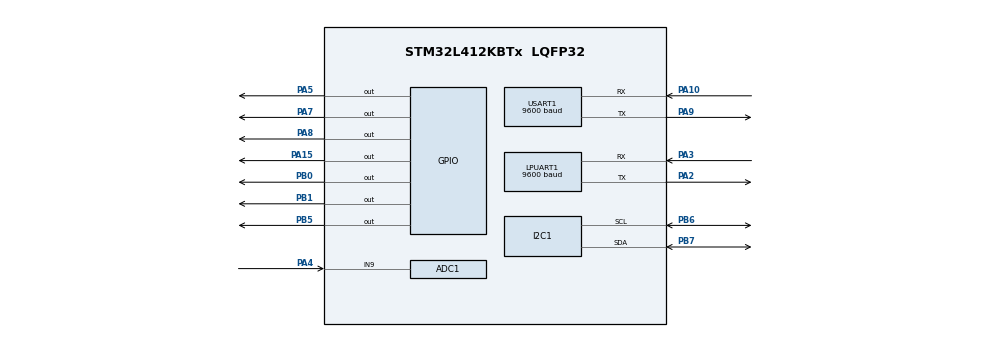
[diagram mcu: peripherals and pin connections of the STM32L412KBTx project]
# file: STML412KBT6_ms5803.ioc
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ADC1.Channel-0\#ChannelRegularConversion=ADC_CHANNEL_9
ADC1.NbrOfConversionFlag=1
ADC1.OffsetNumber-0\#ChannelRegularConversion=ADC_OFFSET_NONE
ADC1.Rank-0\#ChannelRegularConversion=1
ADC1.SamplingTime-0\#ChannelRegularConversion=ADC_SAMPLETIME_2CYCLES_5
ADC1.master=1
I2C1.Timing=0x10D19CE4
LPUART1.BaudRate=9600
LPUART1.WordLength=UART_WORDLENGTH_8B
Mcu.Family=STM32L4
Mcu.Name=STM32L412KBTx
Mcu.Package=LQFP32
NVIC.I2C1_ER_IRQn=true\:0\:0\:false\:false\:true\:true\:true\:true
NVIC.I2C1_EV_IRQn=true\:0\:0\:false\:false\:true\:true\:true\:true
NVIC.LPUART1_IRQn=true\:0\:0\:false\:false\:true\:true\:true\:true
NVIC.PriorityGroup=NVIC_PRIORITYGROUP_4
NVIC.RTC_Alarm_IRQn=true\:0\:0\:false\:false\:true\:true\:true\:true
NVIC.USART1_IRQn=true\:0\:0\:false\:false\:true\:true\:true\:true
PA10.Mode=Asynchronous
PA10.Signal=USART1_RX
PA15\ (JTDI).Signal=GPIO_Output
PA2.Mode=Asynchronous
PA2.Signal=LPUART1_TX
PA3.Mode=Asynchronous
PA3.Signal=LPUART1_RX
PA4.Signal=ADCx_IN9
PA5.Signal=GPIO_Output
PA7.Signal=GPIO_Output
PA8.Signal=GPIO_Output
PA9.Mode=Asynchronous
PA9.Signal=USART1_TX
PB0.Signal=GPIO_Output
PB1.Signal=GPIO_Output
PB5.Signal=GPIO_Output
PB6.Mode=I2C
PB6.Signal=I2C1_SCL
PB7.Mode=I2C
PB7.Signal=I2C1_SDA
PC14-OSC32_IN\ (PC14).Mode=LSE-External-Oscillator
PC14-OSC32_IN\ (PC14).Signal=RCC_OSC32_IN
PC15-OSC32_OUT\ (PC15).Mode=LSE-External-Oscillator
PC15-OSC32_OUT\ (PC15).Signal=RCC_OSC32_OUT
ProjectManager.HeapSize=0x200
ProjectManager.StackSize=0x400
ProjectManager.TargetToolchain=Makefile
RCC.ADCFreq_Value=80000000
RCC.AHBFreq_Value=80000000
RCC.APB1Freq_Value=80000000
RCC.APB1TimFreq_Value=80000000
RCC.APB2Freq_Value=80000000
RCC.APB2TimFreq_Value=80000000
RCC.CortexFreq_Value=80000000
RCC.HCLKFreq_Value=80000000
RCC.HSE_VALUE=8000000
RCC.HSI48_VALUE=48000000
RCC.HSI_VALUE=16000000
RCC.LPUART1CLockSelection=RCC_LPUART1CLKSOURCE_HSI
RCC.MSI_VALUE=4000000
RCC.PLLM=2
RCC.PLLN=20
RCC.PLLSourceVirtual=RCC_PLLSOURCE_HSI
RCC.RTCClockSelection=RCC_RTCCLKSOURCE_LSE
RCC.SYSCLKFreq_VALUE=80000000
RCC.SYSCLKSource=RCC_SYSCLKSOURCE_PLLCLK
RCC.USBFreq_Value=4000000
RCC.VCOOutputFreq_Value=160000000
RTC.Alarm=RTC_ALARM_A
SH.ADCx_IN9.0=ADC1_IN9,IN9-Single-Ended
USART1.BaudRate=9600
USART1.VirtualMode-Asynchronous=VM_ASYNC
VP_RTC_VS_RTC_Activate.Mode=RTC_Enabled
VP_RTC_VS_RTC_Alarm_A_Intern.Mode=Alarm A
VP_RTC_VS_RTC_Calendar.Mode=RTC_Calendar
board=custom

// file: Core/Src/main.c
/* USER CODE BEGIN Header */
/**
 ******************************************************************************
 * @file           : main.c
 * @brief          : Main program body
 ******************************************************************************
 * @attention
 *
 * Copyright (c) 2024 STMicroelectronics.
 * All rights reserved.
 *
 * This software is licensed under terms that can be found in the LICENSE file
 * in the root directory of this software component.
 * If no LICENSE file comes with this software, it is provided AS-IS.
 *
 ******************************************************************************
 */
/* USER CODE END Header */
#include "main.h"
#include "rtc.h"
#include "flash.h"
/* USER CODE BEGIN Includes */

  static void MX_GPIO_Init(void);
  static void MX_I2C1_Init(void);
  static void MX_ADC1_Init(void);
  static void MX_USART1_UART_Init(void);
  static void MX_LPUART1_UART_Init(void);
  static void MX_IWDG_Init(void);

  // 添加头文件
#include <stdio.h>

typedef enum {
    COLD_BOOT = 0,
    WAKEUP_FROM_PA0,
    WAKEUP_FROM_RTC,
    WAKEUP_FROM_UNKNOWN
} wakeup_source_t;

wakeup_source_t check_wakeup_source(void)
{
    // 必须先使能PWR时钟才能读取标志
    LL_APB1_GRP1_EnableClock(LL_APB1_GRP1_PERIPH_PWR);

    // 检查Standby唤醒标志
    if (LL_PWR_IsActiveFlag_SB() != RESET) {
        // 检查具体的唤醒源
        if (LL_PWR_IsActiveFlag_WU1() != RESET) {
            LL_PWR_ClearFlag_WU1();
            LL_PWR_ClearFlag_SB();
            return WAKEUP_FROM_PA0;
        }
        else if (LL_RTC_IsActiveFlag_ALRA(RTC) != RESET) {
            LL_RTC_ClearFlag_ALRA(RTC);
            LL_PWR_ClearFlag_SB();
            return WAKEUP_FROM_RTC;
        }
        else {
            LL_PWR_ClearFlag_SB();
            return WAKEUP_FROM_UNKNOWN;
        }
    }

    return COLD_BOOT;
}

#include "flash_test.h"

uint8_t wakeup_source = 0;
int main(void)
{
  /* MCU配置部分保持不变 */
    LL_APB2_GRP1_EnableClock(LL_APB2_GRP1_PERIPH_SYSCFG);
    LL_APB1_GRP1_EnableClock(LL_APB1_GRP1_PERIPH_PWR);

    /* 系统中断配置 */
    NVIC_SetPriorityGrouping(NVIC_PRIORITYGROUP_4);
    NVIC_SetPriority(SysTick_IRQn, NVIC_EncodePriority(NVIC_GetPriorityGrouping(),15, 0));

    /* 1. 首先检查唤醒源 - 必须在任何外设初始化之前 */
    wakeup_source = check_wakeup_source();

    /* 2. 配置系统时钟 */
    SystemClock_Config();

    /* 3. 初始化必要的外设 */
    MX_GPIO_Init();
    MX_I2C1_Init();
    MX_ADC1_Init();
    MX_USART1_UART_Init();
    MX_LPUART1_UART_Init();
    MX_RTC_Init();  // 取消注释
    LL_GPIO_ResetOutputPin(GPIOB, LL_GPIO_PIN_1);
    /* 主循环 */
    initial_application();
    while (1)
    {
        exec();
    }
}

void SystemClock_Config(void)
{
  volatile uint32_t i;
  for(i = 0; i < 100000; i++);  // 约10ms延迟
  LL_FLASH_SetLatency(LL_FLASH_LATENCY_4);
  while(LL_FLASH_GetLatency()!= LL_FLASH_LATENCY_4)
  {
  }
  LL_PWR_SetRegulVoltageScaling(LL_PWR_REGU_VOLTAGE_SCALE1);
  while (LL_PWR_IsActiveFlag_VOS() != 0)
  {
  }
  LL_RCC_HSI_Enable();

   /* Wait till HSI is ready */
  while(LL_RCC_HSI_IsReady() != 1)
  {

  }
  LL_RCC_HSI_SetCalibTrimming(64);
  LL_PWR_EnableBkUpAccess();
  LL_RCC_LSE_SetDriveCapability(LL_RCC_LSEDRIVE_LOW);
  LL_RCC_LSE_Enable();

   /* Wait till LSE is ready */
  while(LL_RCC_LSE_IsReady() != 1)
  {

  }
  LL_RCC_PLL_ConfigDomain_SYS(LL_RCC_PLLSOURCE_HSI, LL_RCC_PLLM_DIV_2, 20, LL_RCC_PLLR_DIV_2);
  LL_RCC_PLL_EnableDomain_SYS();
  LL_RCC_PLL_Enable();

   /* Wait till PLL is ready */
  while(LL_RCC_PLL_IsReady() != 1)
  {

  }
  LL_RCC_SetSysClkSource(LL_RCC_SYS_CLKSOURCE_PLL);

   /* Wait till System clock is ready */
  while(LL_RCC_GetSysClkSource() != LL_RCC_SYS_CLKSOURCE_STATUS_PLL)
  {

  }
  LL_RCC_SetAHBPrescaler(LL_RCC_SYSCLK_DIV_1);
  LL_RCC_SetAPB1Prescaler(LL_RCC_APB1_DIV_1);
  LL_RCC_SetAPB2Prescaler(LL_RCC_APB2_DIV_1);

  // 添加LPUART时钟源配置
  LL_RCC_SetLPUARTClockSource(LL_RCC_LPUART1_CLKSOURCE_PCLK1);

  LL_Init1msTick(80000000);

  LL_SetSystemCoreClock(80000000);
  // 启用SysTick中断
  LL_SYSTICK_EnableIT();

}

static void MX_ADC1_Init(void)
{

  LL_ADC_InitTypeDef ADC_InitStruct = {0};
  LL_ADC_REG_InitTypeDef ADC_REG_InitStruct = {0};
  LL_ADC_CommonInitTypeDef ADC_CommonInitStruct = {0};

  LL_GPIO_InitTypeDef GPIO_InitStruct = {0};

  /* Peripheral clock enable */
  LL_AHB2_GRP1_EnableClock(LL_AHB2_GRP1_PERIPH_ADC);

  LL_AHB2_GRP1_EnableClock(LL_AHB2_GRP1_PERIPH_GPIOA);
  /**ADC1 GPIO Configuration
  PA4   ------> ADC1_IN9
  */
  GPIO_InitStruct.Pin = LL_GPIO_PIN_4;
  GPIO_InitStruct.Mode = LL_GPIO_MODE_ANALOG;
  GPIO_InitStruct.Pull = LL_GPIO_PULL_NO;
  LL_GPIO_Init(GPIOA, &GPIO_InitStruct);

  // LL_GPIO_EnablePinAnalogControl(GPIOA,LL_GPIO_PIN_4);

  /** Common config
  */
  ADC_InitStruct.Resolution = LL_ADC_RESOLUTION_12B;
  ADC_InitStruct.DataAlignment = LL_ADC_DATA_ALIGN_RIGHT;
  ADC_InitStruct.LowPowerMode = LL_ADC_LP_MODE_NONE;
  LL_ADC_Init(ADC1, &ADC_InitStruct);
  ADC_REG_InitStruct.TriggerSource = LL_ADC_REG_TRIG_SOFTWARE;
  ADC_REG_InitStruct.SequencerLength = LL_ADC_REG_SEQ_SCAN_DISABLE;
  ADC_REG_InitStruct.SequencerDiscont = LL_ADC_REG_SEQ_DISCONT_DISABLE;
  ADC_REG_InitStruct.ContinuousMode = LL_ADC_REG_CONV_SINGLE;
  ADC_REG_InitStruct.DMATransfer = LL_ADC_REG_DMA_TRANSFER_NONE;
  ADC_REG_InitStruct.Overrun = LL_ADC_REG_OVR_DATA_PRESERVED;
  LL_ADC_REG_Init(ADC1, &ADC_REG_InitStruct);
  LL_ADC_SetOverSamplingScope(ADC1, LL_ADC_OVS_DISABLE);
  ADC_CommonInitStruct.CommonClock = LL_ADC_CLOCK_ASYNC_DIV2;
  ADC_CommonInitStruct.Multimode = LL_ADC_MULTI_INDEPENDENT;
  LL_ADC_CommonInit(__LL_ADC_COMMON_INSTANCE(ADC1), &ADC_CommonInitStruct);
  LL_ADC_SetCommonPathInternalCh(__LL_ADC_COMMON_INSTANCE(ADC1), LL_ADC_PATH_INTERNAL_NONE);

  /* Disable ADC deep power down (enabled by default after reset state) */
  LL_ADC_DisableDeepPowerDown(ADC1);
  /* Enable ADC internal voltage regulator */
  LL_ADC_EnableInternalRegulator(ADC1);
  /* Delay for ADC internal voltage regulator stabilization. */
  /* Compute number of CPU cycles to wait for, from delay in us. */
  /* Note: Variable divided by 2 to compensate partially */
  /* CPU processing cycles (depends on compilation optimization). */
  /* Note: If system core clock frequency is below 200kHz, wait time */
  /* is only a few CPU processing cycles. */
  uint32_t wait_loop_index;
  wait_loop_index = ((LL_ADC_DELAY_INTERNAL_REGUL_STAB_US * (SystemCoreClock / (100000 * 2))) / 10);
  while(wait_loop_index != 0)
  {
    wait_loop_index--;
  }

  /** Configure Regular Channel
  */
  LL_ADC_REG_SetSequencerRanks(ADC1, LL_ADC_REG_RANK_1, LL_ADC_CHANNEL_9);
  LL_ADC_SetChannelSamplingTime(ADC1, LL_ADC_CHANNEL_9, LL_ADC_SAMPLINGTIME_47CYCLES_5);
  LL_ADC_SetChannelSingleDiff(ADC1, LL_ADC_CHANNEL_9, LL_ADC_SINGLE_ENDED);
  /* USER CODE BEGIN ADC1_Init 2 */
  LL_ADC_StartCalibration(ADC1,LL_ADC_SINGLE_ENDED);
  /* USER CODE END ADC1_Init 2 */
}

static void MX_I2C1_Init(void)
{
  /* USER CODE END I2C1_Init 0 */

  LL_I2C_InitTypeDef I2C_InitStruct = {0};

  LL_GPIO_InitTypeDef GPIO_InitStruct = {0};

  LL_RCC_SetI2CClockSource(LL_RCC_I2C1_CLKSOURCE_PCLK1);

  LL_AHB2_GRP1_EnableClock(LL_AHB2_GRP1_PERIPH_GPIOB);
  /**I2C1 GPIO Configuration
  PB6   ------> I2C1_SCL
  PB7   ------> I2C1_SDA
  */
  GPIO_InitStruct.Pin = LL_GPIO_PIN_6|LL_GPIO_PIN_7;
  GPIO_InitStruct.Mode = LL_GPIO_MODE_ALTERNATE;
  GPIO_InitStruct.Speed = LL_GPIO_SPEED_FREQ_VERY_HIGH;
  GPIO_InitStruct.OutputType = LL_GPIO_OUTPUT_OPENDRAIN;
  GPIO_InitStruct.Pull = LL_GPIO_PULL_NO;
  GPIO_InitStruct.Alternate = LL_GPIO_AF_4;
  LL_GPIO_Init(GPIOB, &GPIO_InitStruct);

  /* Peripheral clock enable */
  LL_APB1_GRP1_EnableClock(LL_APB1_GRP1_PERIPH_I2C1);

  /* I2C1 interrupt Init */

  /** I2C Initialization
  */
  LL_I2C_EnableAutoEndMode(I2C1);
  LL_I2C_DisableOwnAddress2(I2C1);
  LL_I2C_DisableGeneralCall(I2C1);
  LL_I2C_EnableClockStretching(I2C1);
  I2C_InitStruct.PeripheralMode = LL_I2C_MODE_I2C;
  I2C_InitStruct.Timing = 0x10D19CE4;
  I2C_InitStruct.AnalogFilter = LL_I2C_ANALOGFILTER_ENABLE;
  I2C_InitStruct.DigitalFilter = 0;
  I2C_InitStruct.OwnAddress1 = 0;
  I2C_InitStruct.TypeAcknowledge = LL_I2C_ACK;
  I2C_InitStruct.OwnAddrSize = LL_I2C_OWNADDRESS1_7BIT;
  LL_I2C_Init(I2C1, &I2C_InitStruct);
  LL_I2C_SetOwnAddress2(I2C1, 0, LL_I2C_OWNADDRESS2_NOMASK);
  /* USER CODE BEGIN I2C1_Init 2 */
  LL_I2C_Enable(I2C1);
  LL_I2C_EnableAutoEndMode(I2C1);
  LL_I2C_EnableOwnAddress1(I2C1);

}

static void MX_USART1_UART_Init(void)
{

  LL_USART_InitTypeDef USART_InitStruct = {0};

  LL_GPIO_InitTypeDef GPIO_InitStruct = {0};

  LL_RCC_SetUSARTClockSource(LL_RCC_USART1_CLKSOURCE_PCLK2);

  /* Peripheral clock enable */
  LL_APB2_GRP1_EnableClock(LL_APB2_GRP1_PERIPH_USART1);

  LL_AHB2_GRP1_EnableClock(LL_AHB2_GRP1_PERIPH_GPIOA);
  /**USART1 GPIO Configuration
  PA9   ------> USART1_TX
  PA10   ------> USART1_RX
  */
  GPIO_InitStruct.Pin = LL_GPIO_PIN_9|LL_GPIO_PIN_10;
  GPIO_InitStruct.Mode = LL_GPIO_MODE_ALTERNATE;
  GPIO_InitStruct.Speed = LL_GPIO_SPEED_FREQ_HIGH;
  GPIO_InitStruct.OutputType = LL_GPIO_OUTPUT_PUSHPULL;
  GPIO_InitStruct.Pull = LL_GPIO_PULL_UP;
  GPIO_InitStruct.Alternate = LL_GPIO_AF_7;
  LL_GPIO_Init(GPIOA, &GPIO_InitStruct);

  /* USART1 interrupt Init */
  NVIC_SetPriority(USART1_IRQn, NVIC_EncodePriority(NVIC_GetPriorityGrouping(),0, 0));
  NVIC_EnableIRQ(USART1_IRQn);

  USART_InitStruct.BaudRate = 9600;
  USART_InitStruct.DataWidth = LL_USART_DATAWIDTH_8B;
  USART_InitStruct.StopBits = LL_USART_STOPBITS_1;
  USART_InitStruct.Parity = LL_USART_PARITY_NONE;
  USART_InitStruct.TransferDirection = LL_USART_DIRECTION_TX_RX;
  USART_InitStruct.HardwareFlowControl = LL_USART_HWCONTROL_NONE;
  USART_InitStruct.OverSampling = LL_USART_OVERSAMPLING_16;
  LL_USART_Init(USART1, &USART_InitStruct);
  LL_USART_ConfigAsyncMode(USART1);
  LL_USART_Enable(USART1);
  LL_USART_EnableIT_RXNE(USART1);
}

static void MX_LPUART1_UART_Init(void)
{

  LL_LPUART_InitTypeDef LPUART_InitStruct = {0};

  LL_GPIO_InitTypeDef GPIO_InitStruct = {0};

  LL_RCC_SetLPUARTClockSource(LL_RCC_LPUART1_CLKSOURCE_HSI);

  /* Peripheral clock enable */
  LL_APB1_GRP2_EnableClock(LL_APB1_GRP2_PERIPH_LPUART1);

  LL_AHB2_GRP1_EnableClock(LL_AHB2_GRP1_PERIPH_GPIOA);
  /**LPUART1 GPIO Configuration
  PA2   ------> LPUART1_TX
  PA3   ------> LPUART1_RX
  */
  GPIO_InitStruct.Pin = LL_GPIO_PIN_2|LL_GPIO_PIN_3;
  GPIO_InitStruct.Mode = LL_GPIO_MODE_ALTERNATE;
  GPIO_InitStruct.Speed = LL_GPIO_SPEED_FREQ_VERY_HIGH;
  GPIO_InitStruct.OutputType = LL_GPIO_OUTPUT_PUSHPULL;
  GPIO_InitStruct.Pull = LL_GPIO_PULL_UP;
  GPIO_InitStruct.Alternate = LL_GPIO_AF_8;
  LL_GPIO_Init(GPIOA, &GPIO_InitStruct);

  /* LPUART1 interrupt Init */
  NVIC_SetPriority(LPUART1_IRQn, NVIC_EncodePriority(NVIC_GetPriorityGrouping(),0, 0));
  NVIC_EnableIRQ(LPUART1_IRQn);

  LPUART_InitStruct.BaudRate = 9600;
  LPUART_InitStruct.DataWidth = LL_LPUART_DATAWIDTH_8B;
  LPUART_InitStruct.StopBits = LL_LPUART_STOPBITS_1;
  LPUART_InitStruct.Parity = LL_LPUART_PARITY_NONE;
  LPUART_InitStruct.TransferDirection = LL_LPUART_DIRECTION_TX_RX;
  LPUART_InitStruct.HardwareFlowControl = LL_LPUART_HWCONTROL_NONE;
  LL_LPUART_Init(LPUART1, &LPUART_InitStruct);
  LL_LPUART_Enable(LPUART1);
  // LL_LPUART_ClearFlag_IDLE(LPUART1);
  LL_LPUART_EnableIT_RXNE(LPUART1);

}

static void MX_GPIO_Init(void)
{
  LL_GPIO_InitTypeDef GPIO_InitStruct = {0};

  /* GPIO Ports Clock Enable */
  LL_AHB2_GRP1_EnableClock(LL_AHB2_GRP1_PERIPH_GPIOA);
  LL_AHB2_GRP1_EnableClock(LL_AHB2_GRP1_PERIPH_GPIOB);

  /*用不到的引脚全部配置成模拟，降低功耗*/
  GPIO_InitStruct.Pin = LL_GPIO_PIN_1|LL_GPIO_PIN_5|LL_GPIO_PIN_6|LL_GPIO_PIN_11|LL_GPIO_PIN_12;
  GPIO_InitStruct.Mode = LL_GPIO_MODE_ANALOG;
  GPIO_InitStruct.Pull = LL_GPIO_PULL_NO;
  LL_GPIO_Init(GPIOA, &GPIO_InitStruct);

  GPIO_InitStruct.Pin = LL_GPIO_PIN_3|LL_GPIO_PIN_4;
  GPIO_InitStruct.Mode = LL_GPIO_MODE_ANALOG;
  GPIO_InitStruct.Pull = LL_GPIO_PULL_NO;
  LL_GPIO_Init(GPIOB, &GPIO_InitStruct);

  LL_GPIO_ResetOutputPin(GPIOA, LL_GPIO_PIN_0);
  GPIO_InitStruct.Pin = LL_GPIO_PIN_0;
  GPIO_InitStruct.Mode = LL_GPIO_MODE_INPUT;
  GPIO_InitStruct.Pull = LL_GPIO_PULL_NO;          // 无上下拉
  GPIO_InitStruct.Speed = LL_GPIO_SPEED_FREQ_LOW;
  LL_GPIO_Init(GPIOA, &GPIO_InitStruct);

  /**/
  LL_GPIO_ResetOutputPin(GPIOA, LL_GPIO_PIN_7|LL_GPIO_PIN_8|LL_GPIO_PIN_15);

  /**/
  LL_GPIO_ResetOutputPin(GPIOB, LL_GPIO_PIN_0|LL_GPIO_PIN_1|LL_GPIO_PIN_5);

  /**/
  GPIO_InitStruct.Pin = LL_GPIO_PIN_7|LL_GPIO_PIN_8|LL_GPIO_PIN_15;
  GPIO_InitStruct.Mode = LL_GPIO_MODE_OUTPUT;
  GPIO_InitStruct.Speed = LL_GPIO_SPEED_FREQ_LOW;
  GPIO_InitStruct.OutputType = LL_GPIO_OUTPUT_PUSHPULL;
  GPIO_InitStruct.Pull = LL_GPIO_PULL_NO;
  LL_GPIO_Init(GPIOA, &GPIO_InitStruct);

  /**/
  GPIO_InitStruct.Pin = LL_GPIO_PIN_0|LL_GPIO_PIN_5;
  GPIO_InitStruct.Mode = LL_GPIO_MODE_OUTPUT;
  GPIO_InitStruct.Speed = LL_GPIO_SPEED_FREQ_LOW;
  GPIO_InitStruct.OutputType = LL_GPIO_OUTPUT_PUSHPULL;
  GPIO_InitStruct.Pull = LL_GPIO_PULL_NO;
  LL_GPIO_Init(GPIOB, &GPIO_InitStruct);

  LL_GPIO_SetOutputPin(GPIOB,LL_GPIO_PIN_5);
  LL_GPIO_SetOutputPin(GPIOA,LL_GPIO_PIN_8);

    /* Configure PB1 as output for status indicator */
    GPIO_InitStruct.Pin = LL_GPIO_PIN_1;
    GPIO_InitStruct.Mode = LL_GPIO_MODE_OUTPUT;
    GPIO_InitStruct.OutputType = LL_GPIO_OUTPUT_PUSHPULL;
    GPIO_InitStruct.Pull = LL_GPIO_PULL_NO;
    GPIO_InitStruct.Speed = LL_GPIO_SPEED_FREQ_LOW;
    LL_GPIO_Init(GPIOB, &GPIO_InitStruct);

    /* Set initial state */
    LL_GPIO_SetOutputPin(GPIOB, LL_GPIO_PIN_1);
    LL_GPIO_SetOutputPin(GPIOA, LL_GPIO_PIN_15);

}

/* USER CODE BEGIN 4 */
static void MX_IWDG_Init(void)
{
  /* USER CODE BEGIN IWDG_Init 0 */

  /* USER CODE END IWDG_Init 0 */

  /* USER CODE BEGIN IWDG_Init 1 */

  /* USER CODE END IWDG_Init 1 */
  LL_IWDG_Enable(IWDG);
  LL_IWDG_EnableWriteAccess(IWDG);
  LL_IWDG_SetPrescaler(IWDG, LL_IWDG_PRESCALER_32);
  LL_IWDG_SetReloadCounter(IWDG, 40950);
  while (LL_IWDG_IsReady(IWDG) != 1)
  {
  }

  LL_IWDG_ReloadCounter(IWDG);
  /* USER CODE BEGIN IWDG_Init 2 */

  /* USER CODE END IWDG_Init 2 */

}
/* USER CODE END 4 */

void Error_Handler(void)
{
  /* USER CODE BEGIN Error_Handler_Debug */
//   /* User can add his own implementation to report the HAL error return state */
//   __disable_irq();
//   while (1)
//   {
//   }
  /* USER CODE END Error_Handler_Debug */
}

#ifdef  USE_FULL_ASSERT
/**
  * @brief  Reports the name of the source file and the source line number
  *         where the assert_param error has occurred.
  * @param  file: pointer to the source file name
  * @param  line: assert_param error line source number
  * @retval None
  */
void assert_failed(uint8_t *file, uint32_t line)
{
  /* USER CODE BEGIN 6 */
//   /* User can add his own implementation to report the file name and line number,
//      ex: printf("Wrong parameters value: file %s on line %d\r\n", file, line) */
  /* USER CODE END 6 */
}
#endif /* USE_FULL_ASSERT */
